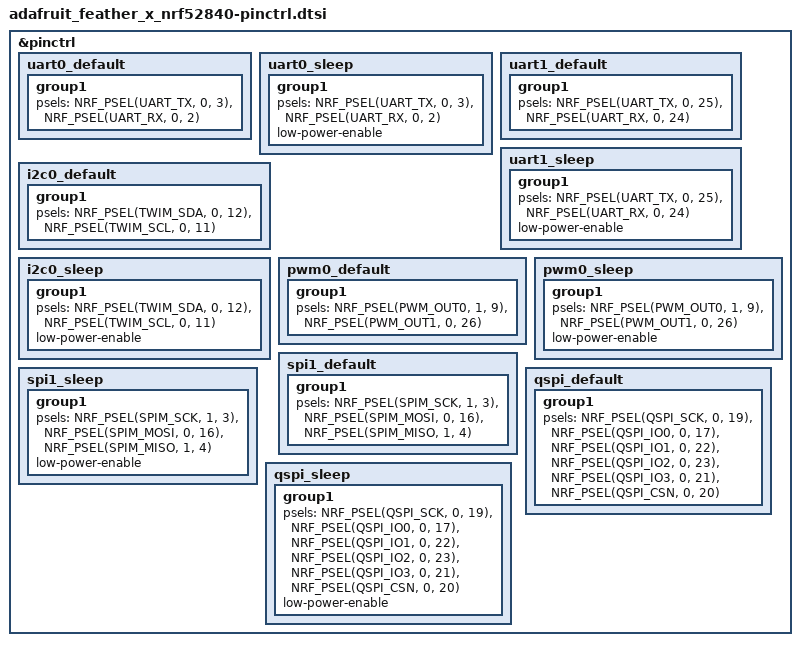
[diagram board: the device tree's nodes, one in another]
/*
 * Copyright (c) 2022 Nordic Semiconductor
 * SPDX-License-Identifier: Apache-2.0
 */

&pinctrl {
	uart0_default: uart0_default {
		group1 {
			psels = <NRF_PSEL(UART_TX, 0, 3)>,
				<NRF_PSEL(UART_RX, 0, 2)>;
		};
	};

	uart0_sleep: uart0_sleep {
		group1 {
			psels = <NRF_PSEL(UART_TX, 0, 3)>,
				<NRF_PSEL(UART_RX, 0, 2)>;
			low-power-enable;
		};
	};

	uart1_default: uart1_default {
		group1 {
			psels = <NRF_PSEL(UART_TX, 0, 25)>,
				<NRF_PSEL(UART_RX, 0, 24)>;
		};
	};

	uart1_sleep: uart1_sleep {
		group1 {
			psels = <NRF_PSEL(UART_TX, 0, 25)>,
				<NRF_PSEL(UART_RX, 0, 24)>;
			low-power-enable;
		};
	};

	i2c0_default: i2c0_default {
		group1 {
			psels = <NRF_PSEL(TWIM_SDA, 0, 12)>,
				<NRF_PSEL(TWIM_SCL, 0, 11)>;
		};
	};

	i2c0_sleep: i2c0_sleep {
		group1 {
			psels = <NRF_PSEL(TWIM_SDA, 0, 12)>,
				<NRF_PSEL(TWIM_SCL, 0, 11)>;
			low-power-enable;
		};
	};

	pwm0_default: pwm0_default {
		group1 {
			psels = <NRF_PSEL(PWM_OUT0, 1, 9)>,
				<NRF_PSEL(PWM_OUT1, 0, 26)>;
			/*nordic,invert;*/
		};
	};

	pwm0_sleep: pwm0_sleep {
		group1 {
			psels = <NRF_PSEL(PWM_OUT0, 1, 9)>,
				<NRF_PSEL(PWM_OUT1, 0, 26)>;
			low-power-enable;
		};
	};

	spi1_default: spi1_default {
		group1 {
			psels = <NRF_PSEL(SPIM_SCK, 1, 3)>, /* Not connected */
				<NRF_PSEL(SPIM_MOSI, 0, 16)>, /* Neopixel */
				<NRF_PSEL(SPIM_MISO, 1, 4)>; /* Not connected */
		};
	};

	spi1_sleep: spi1_sleep {
		group1 {
			psels = <NRF_PSEL(SPIM_SCK, 1, 3)>, /* Not connected */
				<NRF_PSEL(SPIM_MOSI, 0, 16)>, /* Neopixel */
				<NRF_PSEL(SPIM_MISO, 1, 4)>; /* Not connected */
			low-power-enable;
		};
	};

	qspi_default: qspi_default {
		group1 {
			psels = <NRF_PSEL(QSPI_SCK, 0, 19)>,
				<NRF_PSEL(QSPI_IO0, 0, 17)>,
				<NRF_PSEL(QSPI_IO1, 0, 22)>,
				<NRF_PSEL(QSPI_IO2, 0, 23)>,
				<NRF_PSEL(QSPI_IO3, 0, 21)>,
				<NRF_PSEL(QSPI_CSN, 0, 20)>;
		};
	};

	qspi_sleep: qspi_sleep {
		group1 {
			psels = <NRF_PSEL(QSPI_SCK, 0, 19)>,
				<NRF_PSEL(QSPI_IO0, 0, 17)>,
				<NRF_PSEL(QSPI_IO1, 0, 22)>,
				<NRF_PSEL(QSPI_IO2, 0, 23)>,
				<NRF_PSEL(QSPI_IO3, 0, 21)>,
				<NRF_PSEL(QSPI_CSN, 0, 20)>;
			low-power-enable;
		};
	};
};
